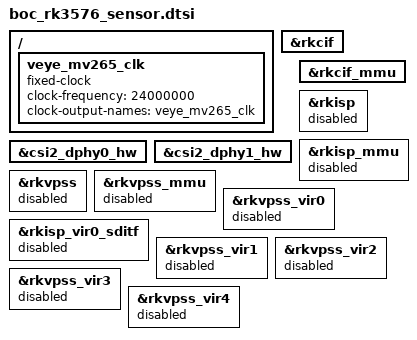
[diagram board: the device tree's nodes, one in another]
#include "boc_rk3576_mipicsi2.dtsi"
// #include "boc_rk3576_mipicsi0_2lane.dtsi"

/ {
	veye_mv265_clk: veye_mv265_clk {
                compatible = "fixed-clock";
                #clock-cells = <0>;
                clock-frequency = <24000000>;
                clock-output-names = "veye_mv265_clk";
        };
};

&rkcif {
        status = "okay";
};

&csi2_dphy0_hw {
        status = "okay";
};

&csi2_dphy1_hw {
        status = "okay";
};

&rkcif_mmu {
        status = "okay";
};

&rkisp {
        status = "disabled";
};

&rkisp_mmu {
        status = "disabled";
};

&rkvpss {
        status = "disabled";
};

&rkvpss_mmu {
        status = "disabled";
};

&rkvpss_vir0 {
        status = "disabled";
};

&rkisp_vir0_sditf {
	status = "disabled";
};

&rkvpss_vir1 {
        status = "disabled";
};

&rkvpss_vir2 {
        status = "disabled";
};

&rkvpss_vir3 {
        status = "disabled";
 };

&rkvpss_vir4 {
        status = "disabled";
 };
